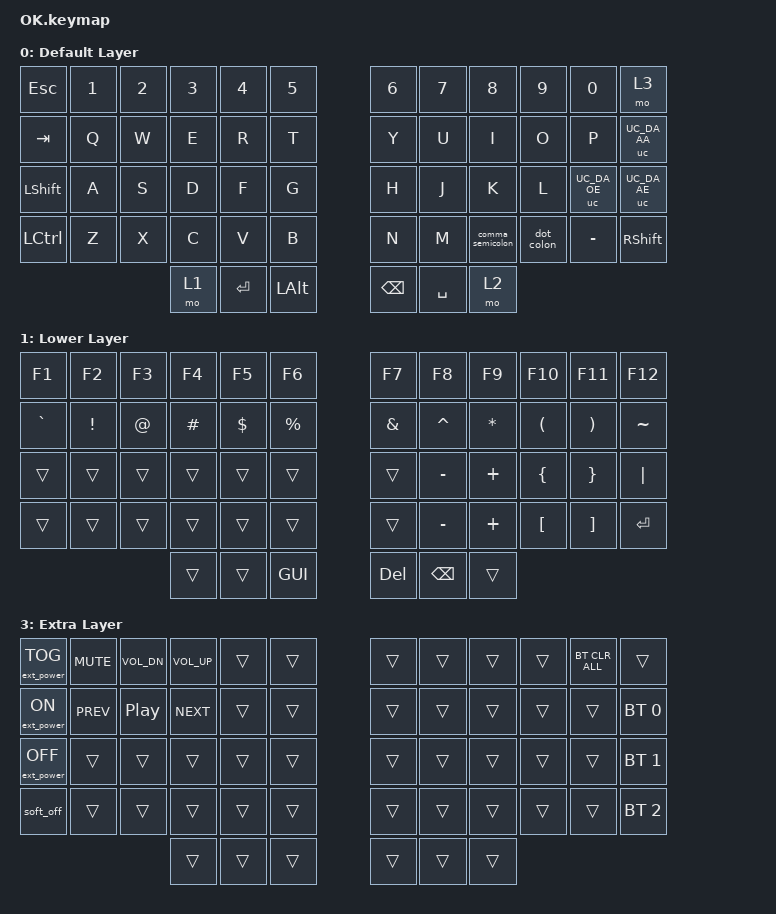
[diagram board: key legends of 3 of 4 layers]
#include <behaviors.dtsi>
#include <behaviors/unicode.dtsi> // For ÆØÅ https://github.com/urob/zmk-unicode?tab=readme-ov-file
#include <dt-bindings/zmk/keys.h>
#include <dt-bindings/zmk/bt.h>
#include <dt-bindings/zmk/ext_power.h>

&soft_off {
    hold-time-ms = <5000>; // Only turn off it the key is held for 5 seconds or longer.
};

/ {
    behaviors {
        comma_semicolon: comma_semicolon {
            compatible = "zmk,behavior-mod-morph";
            #binding-cells = <0>;
            bindings = <&kp COMMA>, <&kp SEMI>;
            mods = <(MOD_LSFT|MOD_RSFT)>;
        };
        dot_colon: dot_colon {
           compatible = "zmk,behavior-mod-morph";
           #binding-cells = <0>;
           bindings = <&kp DOT>, <&kp COLON>;
           mods = <(MOD_LSFT|MOD_RSFT)>;
        };
    };


    keymap {
        compatible = "zmk,keymap";

        default_layer {
            display-name = "Default Layer";
// ------------------------------------------------------------------------------------------------------------
// |  ESC  |  1  |  2  |  3   |  4   |  5   |                   |  6   |  7    |  8    |  9   |   0   | EXTRA |
// |  TAB  |  Q  |  W  |  E   |  R   |  T   |                   |  Y   |  U    |  I    |  O   |   P   |   Å   |
// | SHIFT |  A  |  S  |  D   |  F   |  G   |                   |  H   |  J    |  K    |  L   |   Ø   |   Æ   |
// |  CTRL |  Z  |  X  |  C   |  V   |  B   |                   |  N   |  M    |  ,;   |  .:   |   -   | SHIFT |
//                                | LOWER | ENTER | ALT |    | BACKSPACE | SPACE | RAISE |
            bindings = <
&kp ESC   &kp N1 &kp N2 &kp N3   &kp N4   &kp N5                    &kp N6 &kp N7   &kp N8            &kp N9     &kp N0       &mo 3
&kp TAB   &kp Q  &kp W  &kp E    &kp R    &kp T                     &kp Y  &kp U    &kp I             &kp O      &kp P        &uc UC_DA_AA
&kp LSHFT &kp A  &kp S  &kp D    &kp F    &kp G                     &kp H  &kp J    &kp K             &kp L      &uc UC_DA_OE &uc UC_DA_AE
&kp LCTRL &kp Z  &kp X  &kp C    &kp V    &kp B                     &kp N  &kp M    &comma_semicolon  &dot_colon &kp MINUS    &kp RSHFT
                                    &mo 1 &kp RET &kp LALT    &kp BACKSPACE &kp SPACE  &mo 2
            >;

            /* sensor-bindings = <&inc_dec_kp C_VOL_UP C_VOL_DN>; */
        };

        lower_layer {
            display-name = "Lower Layer";
// ------------------------------------------------------------------------------------------------------------
// |  F1   |  F2 |  F3 |  F4  |  F5  |  F6  |                   |  F7  |  F8   |  F9   |  F10 |  F11  |  F12  |
// |   `   |  !  |  @  |  #   |  $   |  %   |                   |  &   |  ^    |  *    |  (   |   )   |   ~   |
// |       |     |     |      |      |      |                   |      |  _    |  +    |  {   |   }   |  "|"  |
// |       |     |     |      |      |      |                   |      |  _    |  +    |  [   |   ]   | ENTER |
//                     |      |      |      |  GUI  |  | DELETE  |      |       |       |
            bindings = <
&kp F1     &kp F2           &kp F3            &kp F4            &kp F5       &kp F6                       &kp F7    &kp F8    &kp F9    &kp F10   &kp F11   &kp F12
&kp GRAVE  &kp EXCL         &kp AT            &kp HASH          &kp DOLLAR   &kp PRCNT                    &kp AMPS  &kp CARET &kp ASTRK &kp LPAR  &kp RPAR  &kp TILDE
&trans     &trans           &trans            &trans            &trans       &trans                       &trans    &kp MINUS &kp PLUS  &kp LBRC  &kp RBRC  &kp PIPE
&trans     &trans           &trans            &trans            &trans       &trans                       &trans    &kp MINUS &kp PLUS  &kp LBKT  &kp RBKT  &kp RET
                                                          &trans       &trans    &kp GUI             &kp DELETE    &kp BACKSPACE    &trans
            >;

            /* sensor-bindings = <&inc_dec_kp C_VOL_UP C_VOL_DN>; */
        };

        raise_layer {
            display-name = "Raise Layer";
// ------------------------------------------------------------------------------------------------------------
// |  "|"  |     |     |      |      |      |                   |      |       |       |      |       |       |
// |       |     |     |      |      |      |                   |      |       |       |      |       |       |
// |       |     |     |      |      |      |                   |      |   <-  |   v   |  ^   |  ->   |       |
// |       |     |     |      |      |      |                   |      |       |       |      |       |       |
//                            |      |      |  GUI   |  |       |      |       |
            bindings = <
&kp PIPE  &trans &trans &trans  &trans  &trans                       &trans      &trans    &trans    &trans   &trans    &trans
&trans    &trans &trans &trans  &trans  &trans                       &trans      &trans    &trans    &trans   &trans    &trans
&trans    &trans &trans &trans  &trans  &trans                       &trans      &kp LEFT  &kp DOWN  &kp UP   &kp RIGHT &trans
&trans    &trans &trans &trans  &trans  &trans    &trans   &trans    &trans      &trans    &trans    &trans   &trans    &trans
                                &trans  &trans    &kp GUI   &trans    &trans      &trans
            >;

            /* sensor-bindings = <&inc_dec_kp C_VOL_UP C_VOL_DN>; */
        };

        extra_layer {
            display-name = "Extra Layer";
// ------------------------------------------------------------------------------------------------------------
// | POWER TOGGLE |   MUTE     |     VOL DOWN    |    VOL UP     |        |        |                   |      |       |       |      |          |       |
// |  POWER ON    |   PREV     |    PLAY/PAUSE   |     NEXT      |        |        |                   |      |       |       |      | BT CLEAR |  BT0  |
// |  POWER OFF   |            |                 |               |        |        |                   |      |       |       |      |          |  BT1  |
// |  SOFT OFF    |            |                 |               |        |        |                   |      |       |       |      |          |  BT2  |
//                                                     |          |             |          |   |          |          |          |
            bindings = <
&ext_power EP_TOG    &kp C_MUTE  &kp C_VOL_DN       &kp C_VOL_UP    &trans  &trans                       &trans      &trans    &trans    &trans   &bt BT_CLR_ALL    &trans
&ext_power EP_ON     &kp C_PREV  &kp C_PLAY_PAUSE   &kp C_NEXT      &trans  &trans                       &trans      &trans    &trans    &trans   &trans            &bt BT_SEL 0
&ext_power EP_OFF    &trans      &trans             &trans          &trans  &trans                       &trans      &trans    &trans    &trans   &trans            &bt BT_SEL 1
&soft_off            &trans      &trans             &trans          &trans  &trans                       &trans      &trans    &trans    &trans   &trans            &bt BT_SEL 2
                                                           &trans     &trans      &trans           &trans    &trans      &trans
            >;

            /* sensor-bindings = <&inc_dec_kp C_VOL_UP C_VOL_DN>; */
        };
    };
};
